# ATmega32C1 device description
Architecture: AVR8; Family: megaAVR
Registers are 8-bit, access not given, no defined reset value unless marked. A register's access mark holds for its fields unless they carry their own. Offsets are from the block's base; [hi:lo] are bit positions.

## CAN — Controller Area Network
Instances: CAN 0x00
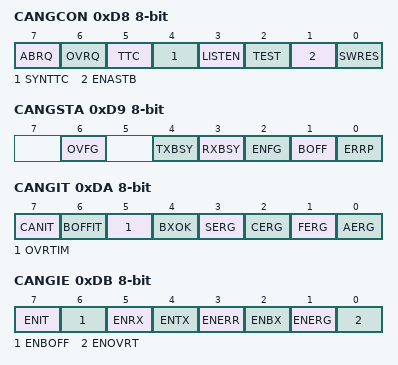
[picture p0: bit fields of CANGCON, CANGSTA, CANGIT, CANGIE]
0xD8 CANGCON — CAN General Control Register
  [7] ABRQ — Abort Request
  [6] OVRQ — Overload Frame Request
  [5] TTC — Time Trigger Communication
  [4] SYNTTC — Synchronization of TTC
  [3] LISTEN — Listening Mode
  [2] TEST — Test Mode
  [1] ENASTB — Enable / Standby
  [0] SWRES — Software Reset Request
0xD9 CANGSTA — CAN General Status Register
  [6] OVFG — Overload Frame Flag
  [4] TXBSY — Transmitter Busy
  [3] RXBSY — Receiver Busy
  [2] ENFG — Enable Flag
  [1] BOFF — Bus Off Mode
  [0] ERRP — Error Passive Mode
0xDA CANGIT — CAN General Interrupt Register Flags
  [7] CANIT — General Interrupt Flag
  [6] BOFFIT — Bus Off Interrupt Flag
  [5] OVRTIM — Overrun CAN Timer Flag
  [4] BXOK — Burst Receive Interrupt Flag
  [3] SERG — Stuff Error General Flag
  [2] CERG — CRC Error General Flag
  [1] FERG — Form Error General Flag
  [0] AERG — Ackknowledgement Error General Flag
0xDB CANGIE — CAN General Interrupt Enable Register
  [7] ENIT — Enable all Interrupts
  [6] ENBOFF — Enable Bus Off Interrupt
  [5] ENRX — Enable Receive Interrupt
  [4] ENTX — Enable Transmitt Interrupt
  [3] ENERR — Enable MOb Error Interrupt
  [2] ENBX — Enable Burst Receive Interrupt
  [1] ENERG — Enable General Error Interrupt
  [0] ENOVRT — Enable CAN Timer Overrun Interrupt
0xDC CANEN2 — Enable MOb Register 2
  [5:0] ENMOB — Enable MObs
0xDD CANEN1 — Enable MOb Register 1(empty)
0xDE CANIE2 — Enable Interrupt MOb Register 2
  [5:0] IEMOB — Interrupt Enable MObs
0xDF CANIE1 — Enable Interrupt MOb Register 1 (empty)
0xE0 CANSIT2 — CAN Status Interrupt MOb Register 2
  [5:0] SIT — Status of Interrupt MObs
0xE1 CANSIT1 — CAN Status Interrupt MOb Register 1 (empty)
0xE2 CANBT1 — CAN Bit Timing Register 1
  [6:1] BRP — Baud Rate Prescaler bits
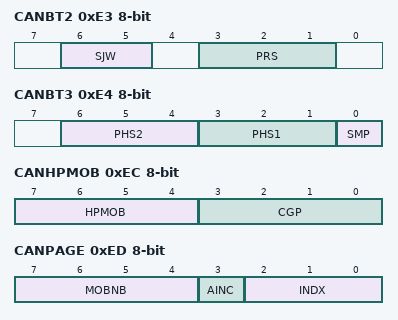
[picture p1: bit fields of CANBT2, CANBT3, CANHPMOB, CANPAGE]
0xE3 CANBT2 — CAN Bit Timing Register 2
  [6:5] SJW — Re-Sync Jump Width bits
  [3:1] PRS — Propagation Time Segment bits
0xE4 CANBT3 — CAN Bit Timing Register 3
  [6:4] PHS2 — Phase Segment 2 bits
  [3:1] PHS1 — Phase Segment 1 bits
  [0] SMP — Sample Type
0xE5 CANTCON — Timer Control Register
  [7:0] TPRSC — Timer Control bits
0xE6 CANTIM 16-bit — Timer Register
  [15:0] CANTIM — CAN Timer bits
0xE8 CANTTC 16-bit — TTC Timer Register
  [15:0] TIMTTC — TTC Timer Count
0xEA CANTEC — Transmit Error Counter Register
  [7:0] TEC — Transmit Error Counter bits
0xEB CANREC — Receive Error Counter Register
  [7:0] REC — Receive Error Counter bits
0xEC CANHPMOB — Highest Priority MOb Register
  [7:4] HPMOB — Highest Priority MOb Number bits
  [3:0] CGP — CAN General Purpose bits
0xED CANPAGE — Page MOb Register
  [7:4] MOBNB — MOb Number bits
  [3] AINC — MOb Data Buffer Auto Increment (Active Low)
  [2:0] INDX — Data Buffer Index bits
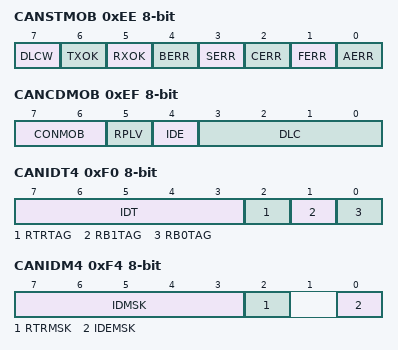
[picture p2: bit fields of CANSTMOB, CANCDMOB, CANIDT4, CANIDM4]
0xEE CANSTMOB — MOb Status Register
  [7] DLCW — Data Length Code Warning on MOb
  [6] TXOK — Transmit OK on MOb
  [5] RXOK — Receive OK on MOb
  [4] BERR — Bit Error on MOb
  [3] SERR — Stuff Error on MOb
  [2] CERR — CRC Error on MOb
  [1] FERR — Form Error on MOb
  [0] AERR — Ackknowledgement Error on MOb
0xEF CANCDMOB — MOb Control and DLC Register
  [7:6] CONMOB — MOb Config bits
  [5] RPLV — Reply Valid
  [4] IDE — Identifier Extension
  [3:0] DLC — Data Length Code bits
0xF0 CANIDT4 — Identifier Tag Register 4
  [7:3] IDT — Identifier Tag
  [2] RTRTAG — Remote Transmission Request Tag
  [1] RB1TAG — Reserved Bit 1 Tag
  [0] RB0TAG — Reserved Bit 0 Tag
0xF1 CANIDT3 — Identifier Tag Register 3
  [7:0] IDT (bit 5 of the value upward) — Identifier Tag
0xF2 CANIDT2 — Identifier Tag Register 2
  [7:0] IDT (bit 13 of the value upward) — Identifier Tag
0xF3 CANIDT1 — Identifier Tag Register 1
  [7:0] IDT (bit 21 of the value upward) — Identifier Tag
0xF4 CANIDM4 — Identifier Mask Register 4
  [7:3] IDMSK — Identifier Mask
  [2] RTRMSK — Remote Transmission Request Mask
  [0] IDEMSK — Identifier Extension Mask
0xF5 CANIDM3 — Identifier Mask Register 3
  [7:0] IDMSK (bit 5 of the value upward) — Identifier Mask
0xF6 CANIDM2 — Identifier Mask Register 2
  [7:0] IDMSK (bit 13 of the value upward) — Identifier Mask
0xF7 CANIDM1 — Identifier Mask Register 1
  [7:0] IDMSK (bit 21 of the value upward) — Identifier Mask
0xF8 CANSTM 16-bit — Time Stamp Register
  [15:0] TIMSTM
0xFA CANMSG — Message Data Register
  [7:0] MSG — Message Data bits
